# STM32L031K6U7 register map
File version: 1.0
Registers are 32-bit, access not given, reset 0x0 unless marked. A register's access mark holds for its fields unless they carry their own. Offsets are from the block's base; [hi:lo] are bit positions; {n}, {i} and the like mark numbered series; 'fields as' and 'values as' point back to an identical list.

## SYSCFG
Base 0x40010000
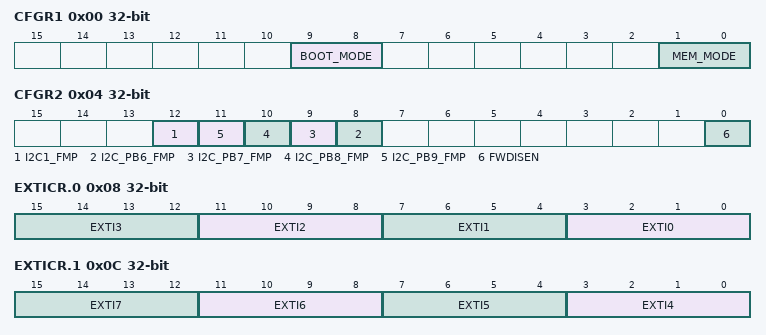
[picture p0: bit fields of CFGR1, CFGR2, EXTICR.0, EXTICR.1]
0x00 CFGR1
  [9:8] BOOT_MODE, [1:0] MEM_MODE
0x04 CFGR2
  [12] I2C1_FMP, [n+2] I2C_PB{n}_FMP (n=6..9), [0] FWDISEN
0x08 EXTICR.0
  [4n+3:4n] EXTI{n} (n=0..3)
0x0C EXTICR.1
  [4n-13:4n-16] EXTI{n} (n=4..7)
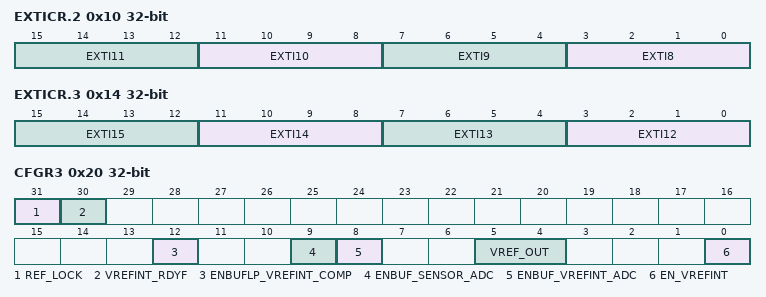
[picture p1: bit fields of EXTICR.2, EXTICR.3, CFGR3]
0x10 EXTICR.2
  [4n-29:4n-32] EXTI{n} (n=8..11)
0x14 EXTICR.3
  [4n-45:4n-48] EXTI{n} (n=12..15)
0x20 CFGR3
  [31] REF_LOCK, [30] VREFINT_RDYF, [12] ENBUFLP_VREFINT_COMP, [9] ENBUF_SENSOR_ADC, [8] ENBUF_VREFINT_ADC, [5:4] VREF_OUT, [0] EN_VREFINT

## COMP12_COMMON
Base 0x40010018
Same registers: COMP1 0x40010018
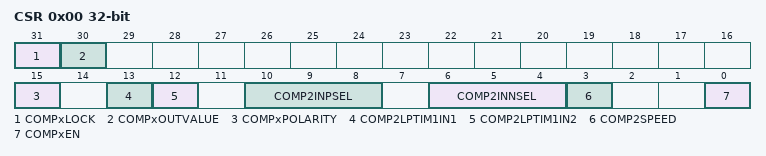
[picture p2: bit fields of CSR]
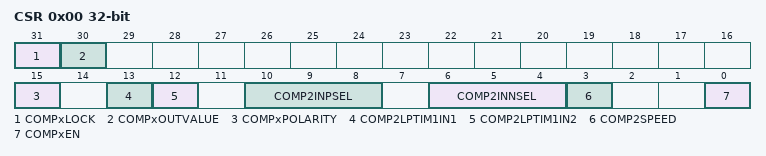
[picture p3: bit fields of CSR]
0x00 CSR
  [31] COMPxLOCK, [30] COMPxOUTVALUE, [15] COMPxPOLARITY, [13] COMP2LPTIM1IN1, [12] COMP2LPTIM1IN2, [10:8] COMP2INPSEL, [6:4] COMP2INNSEL, [3] COMP2SPEED, [0] COMPxEN

## COMP2
Base 0x4001001C
0x00 CSR
  [31] COMPxLOCK, [30] COMPxOUTVALUE, [15] COMPxPOLARITY, [13] COMP2LPTIM1IN1, [12] COMP2LPTIM1IN2, [10:8] COMP2INPSEL, [6:4] COMP2INNSEL, [3] COMP2SPEED, [0] COMPxEN

## EXTI
Base 0x40010400
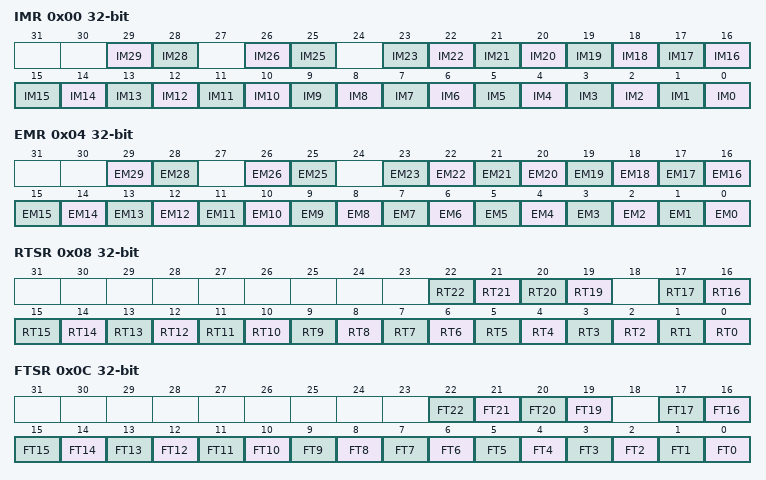
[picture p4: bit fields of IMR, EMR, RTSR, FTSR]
0x00 IMR
  [29] IM29, [28] IM28, [26] IM26, [25] IM25, [n] IM{n} (n=0..23)
0x04 EMR
  [29] EM29, [28] EM28, [26] EM26, [25] EM25, [n] EM{n} (n=0..23)
0x08 RTSR
  [n] RT{n} (n=19..22), [n] RT{n} (n=0..17)
0x0C FTSR
  [n] FT{n} (n=19..22), [n] FT{n} (n=0..17)
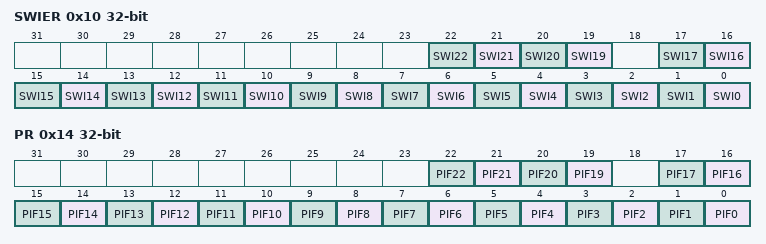
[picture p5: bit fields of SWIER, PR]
0x10 SWIER
  [n] SWI{n} (n=19..22), [n] SWI{n} (n=0..17)
0x14 PR
  [n] PIF{n} (n=19..22), [n] PIF{n} (n=0..17)

## ADC1
Base 0x40012400
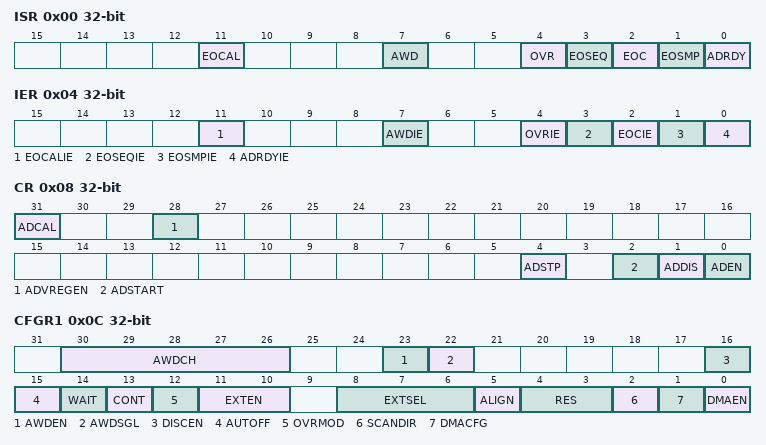
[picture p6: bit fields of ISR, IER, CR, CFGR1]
0x00 ISR
  [11] EOCAL, [7] AWD, [4] OVR, [3] EOSEQ, [2] EOC, [1] EOSMP, [0] ADRDY
0x04 IER
  [11] EOCALIE, [7] AWDIE, [4] OVRIE, [3] EOSEQIE, [2] EOCIE, [1] EOSMPIE, [0] ADRDYIE
0x08 CR
  [31] ADCAL, [28] ADVREGEN, [4] ADSTP, [2] ADSTART, [1] ADDIS, [0] ADEN
0x0C CFGR1
  [30:26] AWDCH, [23] AWDEN, [22] AWDSGL, [16] DISCEN, [15] AUTOFF, [14] WAIT, [13] CONT, [12] OVRMOD, [11:10] EXTEN, [8:6] EXTSEL, [5] ALIGN, [4:3] RES, [2] SCANDIR, [1] DMACFG, [0] DMAEN
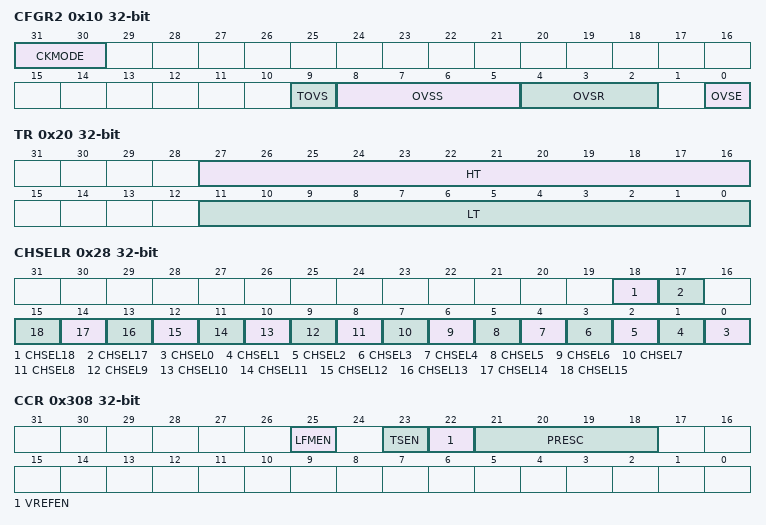
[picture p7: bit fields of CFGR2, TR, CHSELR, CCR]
0x10 CFGR2
  [31:30] CKMODE, [9] TOVS, [8:5] OVSS, [4:2] OVSR, [0] OVSE
0x14 SMPR
  [2:0] SMP
0x20 TR
  [27:16] HT, [11:0] LT
0x28 CHSELR
  [18] CHSEL18, [17] CHSEL17, [n] CHSEL{n} (n=0..15)
0x40 DR
  [15:0] DATA
0xB4 CALFACT
  [6:0] CALFACT
0x308 CCR
  [25] LFMEN, [23] TSEN, [22] VREFEN, [21:18] PRESC

## DMA1
Base 0x40020000
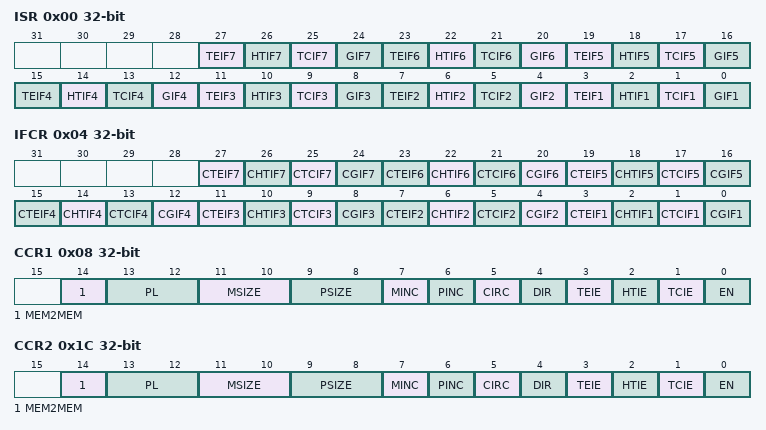
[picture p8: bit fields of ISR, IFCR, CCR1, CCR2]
0x00 ISR
  [4n-1] TEIF{n} (n=1..7), [4n-2] HTIF{n} (n=1..7), [4n-3] TCIF{n} (n=1..7), [4n-4] GIF{n} (n=1..7)
0x04 IFCR
  [4n-1] CTEIF{n} (n=1..7), [4n-2] CHTIF{n} (n=1..7), [4n-3] CTCIF{n} (n=1..7), [4n-4] CGIF{n} (n=1..7)
0x08 CCR1
  [14] MEM2MEM, [13:12] PL, [11:10] MSIZE, [9:8] PSIZE, [7] MINC, [6] PINC, [5] CIRC, [4] DIR, [3] TEIE, [2] HTIE, [1] TCIE, [0] EN
0x0C CNDTR1
  [15:0] NDT
0x10 CPAR1
  [31:0] PA
{0x0+0x14*i} CMAR{i} (i=1..7)
  [31:0] MA
0x1C CCR2
  fields as CCR1
0x20 CNDTR2
  [15:0] NDT
0x24 CPAR2
  [31:0] PA
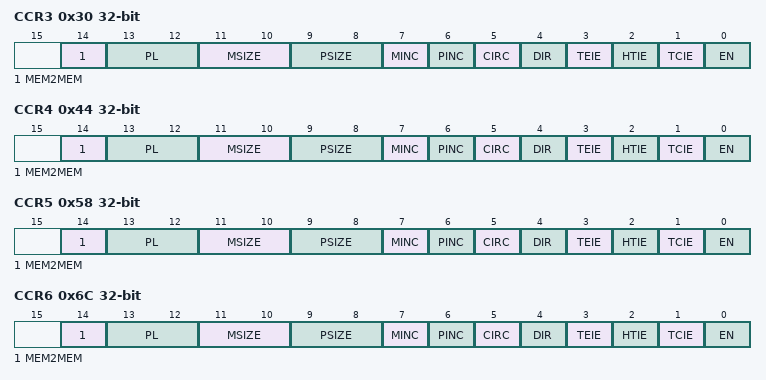
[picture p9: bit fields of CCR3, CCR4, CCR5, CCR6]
0x30 CCR3
  fields as CCR1
0x34 CNDTR3
  [15:0] NDT
0x38 CPAR3
  [31:0] PA
0x44 CCR4
  fields as CCR1
0x48 CNDTR4
  [15:0] NDT
0x4C CPAR4
  [31:0] PA
0x58 CCR5
  fields as CCR1
0x5C CNDTR5
  [15:0] NDT
0x60 CPAR5
  [31:0] PA
0x6C CCR6
  fields as CCR1
0x70 CNDTR6
  [15:0] NDT
0x74 CPAR6
  [31:0] PA
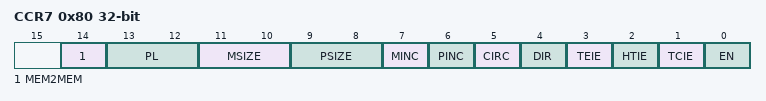
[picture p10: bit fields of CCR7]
0x80 CCR7
  fields as CCR1
0x84 CNDTR7
  [15:0] NDT
0x88 CPAR7
  [31:0] PA

## DMA1_CSELR
Base 0x400200A8
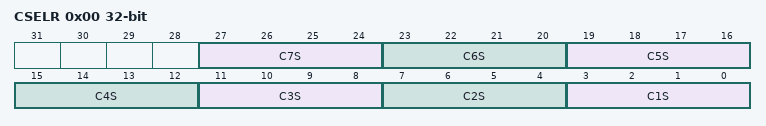
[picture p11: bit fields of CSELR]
0x00 CSELR
  [4n-1:4n-4] C{n}S (n=1..7)

## RCC
Base 0x40021000
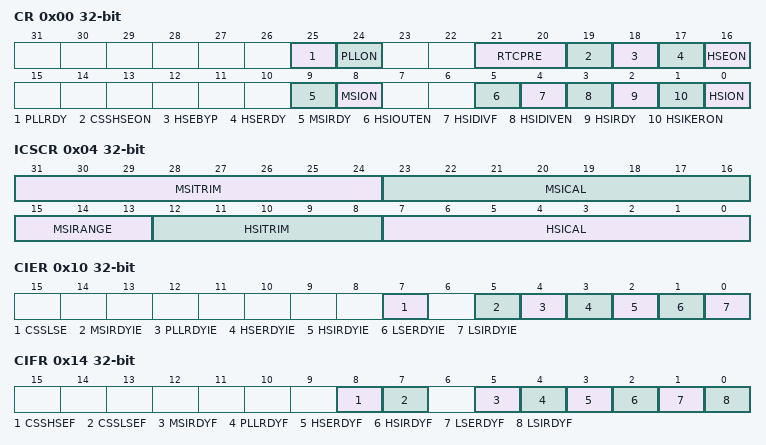
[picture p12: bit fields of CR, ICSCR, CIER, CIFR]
0x00 CR
  [25] PLLRDY, [24] PLLON, [21:20] RTCPRE, [19] CSSHSEON, [18] HSEBYP, [17] HSERDY, [16] HSEON, [9] MSIRDY, [8] MSION, [5] HSIOUTEN, [4] HSIDIVF, [3] HSIDIVEN, [2] HSIRDY, [1] HSIKERON, [0] HSION
0x04 ICSCR
  [31:24] MSITRIM, [23:16] MSICAL, [15:13] MSIRANGE, [12:8] HSITRIM, [7:0] HSICAL
0x08 CRRCR
0x0C CFGR
  [30:28] MCOPRE, [26] MCOSEL_HSE, [26:25] MCOSEL_LSI, [24] MCOSEL_SYSCLK, [23] PLLDIV3, [23:22] PLLDIV4, [21:18] PLLMUL, [16] PLLSRC, [15] STOPWUCK, [13:11] PPRE2, [10:8] PPRE1, [7:4] HPRE, [3:2] SWS, [1:0] SW
0x10 CIER
  [7] CSSLSE, [5] MSIRDYIE, [4] PLLRDYIE, [3] HSERDYIE, [2] HSIRDYIE, [1] LSERDYIE, [0] LSIRDYIE
0x14 CIFR
  [8] CSSHSEF, [7] CSSLSEF, [5] MSIRDYF, [4] PLLRDYF, [3] HSERDYF, [2] HSIRDYF, [1] LSERDYF, [0] LSIRDYF
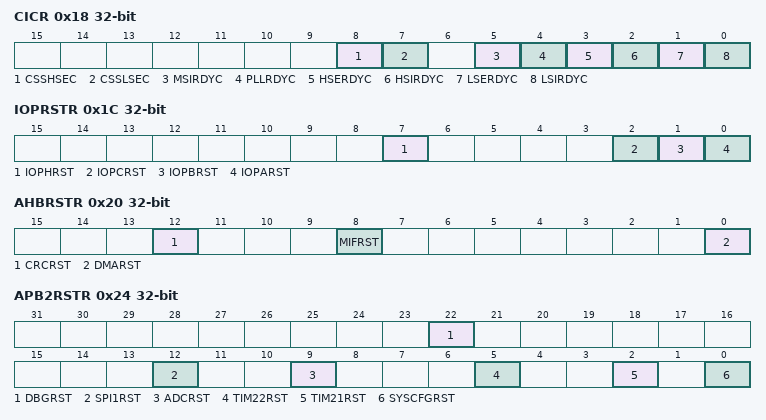
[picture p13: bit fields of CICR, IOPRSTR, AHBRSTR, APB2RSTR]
0x18 CICR
  [8] CSSHSEC, [7] CSSLSEC, [5] MSIRDYC, [4] PLLRDYC, [3] HSERDYC, [2] HSIRDYC, [1] LSERDYC, [0] LSIRDYC
0x1C IOPRSTR
  [7] IOPHRST, [2] IOPCRST, [1] IOPBRST, [0] IOPARST
0x20 AHBRSTR
  [12] CRCRST, [8] MIFRST, [0] DMARST
0x24 APB2RSTR
  [22] DBGRST, [12] SPI1RST, [9] ADCRST, [5] TIM22RST, [2] TIM21RST, [0] SYSCFGRST
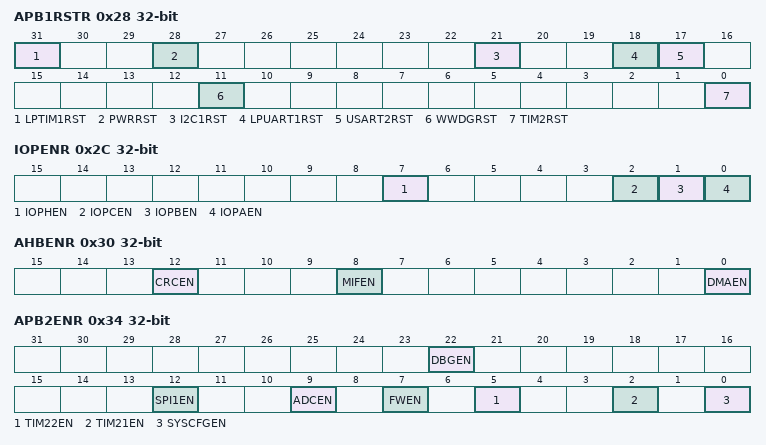
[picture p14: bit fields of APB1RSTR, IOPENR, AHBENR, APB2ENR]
0x28 APB1RSTR
  [31] LPTIM1RST, [28] PWRRST, [21] I2C1RST, [18] LPUART1RST, [17] USART2RST, [11] WWDGRST, [0] TIM2RST
0x2C IOPENR
  [7] IOPHEN, [2] IOPCEN, [1] IOPBEN, [0] IOPAEN
0x30 AHBENR
  [12] CRCEN, [8] MIFEN, [0] DMAEN
0x34 APB2ENR
  [22] DBGEN, [12] SPI1EN, [9] ADCEN, [7] FWEN, [5] TIM22EN, [2] TIM21EN, [0] SYSCFGEN
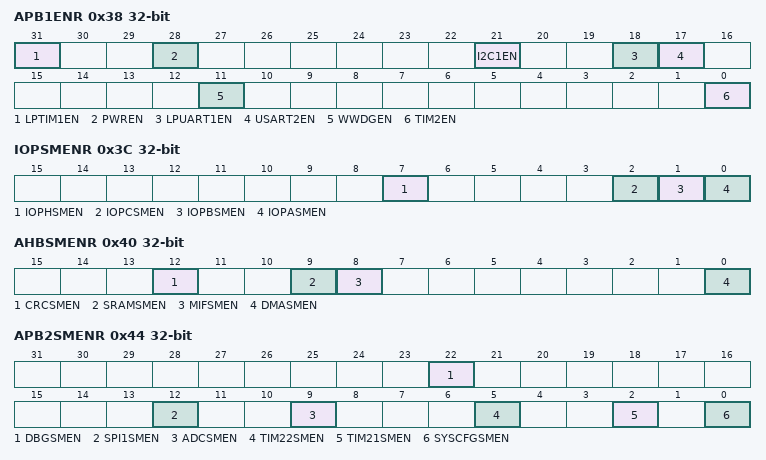
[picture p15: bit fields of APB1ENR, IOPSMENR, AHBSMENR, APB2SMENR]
0x38 APB1ENR
  [31] LPTIM1EN, [28] PWREN, [21] I2C1EN, [18] LPUART1EN, [17] USART2EN, [11] WWDGEN, [0] TIM2EN
0x3C IOPSMENR
  [7] IOPHSMEN, [2] IOPCSMEN, [1] IOPBSMEN, [0] IOPASMEN
0x40 AHBSMENR
  [12] CRCSMEN, [9] SRAMSMEN, [8] MIFSMEN, [0] DMASMEN
0x44 APB2SMENR
  [22] DBGSMEN, [12] SPI1SMEN, [9] ADCSMEN, [5] TIM22SMEN, [2] TIM21SMEN, [0] SYSCFGSMEN
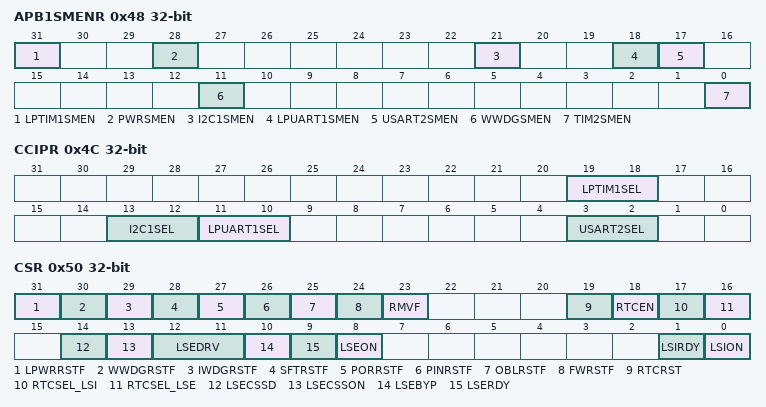
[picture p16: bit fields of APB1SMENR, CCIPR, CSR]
0x48 APB1SMENR
  [31] LPTIM1SMEN, [28] PWRSMEN, [21] I2C1SMEN, [18] LPUART1SMEN, [17] USART2SMEN, [11] WWDGSMEN, [0] TIM2SMEN
0x4C CCIPR
  [19:18] LPTIM1SEL, [13:12] I2C1SEL, [11:10] LPUART1SEL, [3:2] USART2SEL
0x50 CSR
  [31] LPWRRSTF, [30] WWDGRSTF, [29] IWDGRSTF, [28] SFTRSTF, [27] PORRSTF, [26] PINRSTF, [25] OBLRSTF, [24] FWRSTF, [23] RMVF, [19] RTCRST, [18] RTCEN, [17] RTCSEL_LSI, [16] RTCSEL_LSE, [14] LSECSSD, [13] LSECSSON, [12:11] LSEDRV, [10] LSEBYP, [9] LSERDY, [8] LSEON, [1] LSIRDY, [0] LSION

## FLASH
Base 0x40022000
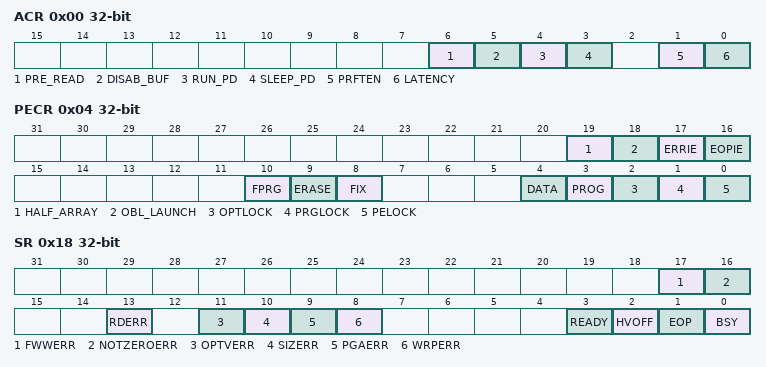
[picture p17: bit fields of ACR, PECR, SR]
0x00 ACR
  [6] PRE_READ, [5] DISAB_BUF, [4] RUN_PD, [3] SLEEP_PD, [1] PRFTEN, [0] LATENCY
0x04 PECR
  [19] HALF_ARRAY, [18] OBL_LAUNCH, [17] ERRIE, [16] EOPIE, [10] FPRG, [9] ERASE, [8] FIX, [4] DATA, [3] PROG, [2] OPTLOCK, [1] PRGLOCK, [0] PELOCK
0x08 PDKEYR
0x0C PEKEYR
0x10 PRGKEYR
0x14 OPTKEYR
0x18 SR
  [17] FWWERR, [16] NOTZEROERR, [13] RDERR, [11] OPTVERR, [10] SIZERR, [9] PGAERR, [8] WRPERR, [3] READY, [2] HVOFF, [1] EOP, [0] BSY
0x1C OPTR
  [31] BOOT1, [22] nRST_STDBY, [21] nRST_STOP, [22:20] USER, [19:16] BOR_LEV, [8] WPRMOD, [7:0] RDPROT
0x20 WRPR
  [15:0] WRP

## CRC
Base 0x40023000
0x00 DR
0x04 IDR 8-bit
0x08 CR
  [7] REV_OUT, [6:5] REV_IN, [4:3] POLYSIZE, [0] RESET
0x10 INIT
0x14 POL

## GPIOA
Base 0x50000000
Same registers: GPIOB 0x50000400, GPIOC 0x50000800, GPIOH 0x50001C00
0x00 MODER
  [2n+1:2n] MODE{n} (n=0..15)
0x04 OTYPER
0x08 OSPEEDR
0x0C PUPDR
  [2n+1:2n] PUPD{n} (n=0..15)
0x10 IDR
  [n] ID{n} (n=0..15)
0x14 ODR
  [n] OD{n} (n=0..15)
0x18 BSRR
0x1C LCKR
  [16] LCKK, [n] LCK{n} (n=0..15)
0x20 AFR.0
  [4n+3:4n] AFSEL{n} (n=0..7)
0x24 AFR.1
  [4n-29:4n-32] AFSEL{n} (n=8..15)
0x28 BRR
